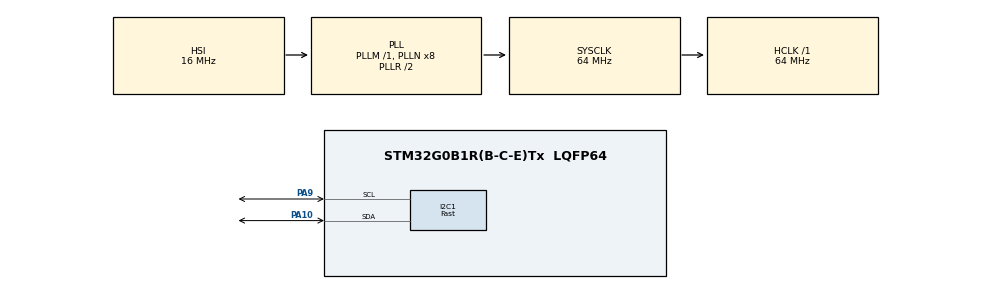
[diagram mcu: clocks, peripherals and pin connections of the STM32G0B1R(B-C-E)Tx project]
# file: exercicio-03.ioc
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I2C1.Analog_Filter=I2C_ANALOGFILTER_DISABLE
I2C1.I2C_Speed_Mode=I2C_Fast
I2C1.Speed=200
I2C1.Timing=0x00603BFF
Mcu.Family=STM32G0
Mcu.Name=STM32G0B1R(B-C-E)Tx
Mcu.Package=LQFP64
PA10.Mode=I2C
PA10.Signal=I2C1_SDA
PA13.Mode=Serial_Wire
PA13.Signal=SYS_SWDIO
PA14-BOOT0.Mode=Serial_Wire
PA14-BOOT0.Signal=SYS_SWCLK
PA9.Mode=I2C
PA9.Signal=I2C1_SCL
ProjectManager.HeapSize=0x200
ProjectManager.StackSize=0x400
ProjectManager.TargetToolchain=STM32CubeIDE
RCC.ADCFreq_Value=64000000
RCC.AHBFreq_Value=64000000
RCC.CortexFreq_Value=64000000
RCC.EXTERNAL_CLOCK_VALUE=48000
RCC.HCLKFreq_Value=64000000
RCC.HSE_VALUE=8000000
RCC.HSI48_VALUE=48000000
RCC.HSI_VALUE=16000000
RCC.LSE_VALUE=32768
RCC.SYSCLKFreq_VALUE=64000000
RCC.SYSCLKSource=RCC_SYSCLKSOURCE_PLLCLK
RCC.USBFreq_Value=48000000
RCC.VCOOutputFreq_Value=128000000
VP_SYS_VS_DBSignals.Mode=DisableDeadBatterySignals
board=custom

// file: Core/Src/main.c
/* USER CODE BEGIN Header */
/**
  ******************************************************************************
  * @file           : main.c
  * @brief          : Main program body
  ******************************************************************************
  * @attention
  *
  * Copyright (c) 2022 STMicroelectronics.
  * All rights reserved.
  *
  * This software is licensed under terms that can be found in the LICENSE file
  * in the root directory of this software component.
  * If no LICENSE file comes with this software, it is provided AS-IS.
  *
  ******************************************************************************
  */
/* USER CODE END Header */
#include "main.h"

/* USER CODE BEGIN Includes */
#include <stdio.h>
#include <stdarg.h>
#include <string.h>
#include "eeprom.h"
/* USER CODE END Includes */

I2C_HandleTypeDef hi2c1;
char memory_dump[1024] = {0}; //8kbit

void SystemClock_Config(void);
static void MX_GPIO_Init(void);
static void MX_I2C1_Init(void);
/* USER CODE BEGIN PFP */
eeprom_t Eeprom;
/* USER CODE END PFP */

/* USER CODE BEGIN 0 */
void vprint(const char *fmt, va_list argp) {
	char string[200];
	if (0 < vsprintf(string, fmt, argp)) // build string
			{
		//HAL_i_Transmit(&huart2, (uint8_t*) string, strlen(string), 0xffffff); // send message via UART
	}
}

void my_printf(const char *fmt, ...) // custom printf() function
{
	va_list argp;
	va_start(argp, fmt);
	vprint(fmt, argp);
	va_end(argp);
}
/* USER CODE END 0 */

int main(void)
{
  /* USER CODE BEGIN 1 */
	uint8_t pDataTx[] = "Pado Labs\n\r";
	uint8_t pDataRx[20];
  /* USER CODE END 1 */

  /* MCU Configuration--------------------------------------------------------*/

  /* Reset of all peripherals, Initializes the Flash interface and the Systick. */
  HAL_Init();

  /* Configure the system clock */
  SystemClock_Config();

  /* Initialize all configured peripherals */
  MX_GPIO_Init();
  MX_I2C1_Init();
  /* USER CODE BEGIN 2 */

  eeprom_init(&Eeprom, &hi2c1, 0xA0, 512);

//  eeprom_write(&Eeprom, 0x10, pDataTx, sizeof(pDataTx));

  eeprom_read(&Eeprom, 0x10, pDataRx, sizeof(pDataTx));
  	//HAL_UART_Transmit(&huart2, (uint8_t*) &memory_dump, sizeof(memory_dump),0xffffff);

  /* USER CODE END 2 */

  /* Infinite loop */
  while (1)
  {

  }
}

void SystemClock_Config(void)
{
  RCC_OscInitTypeDef RCC_OscInitStruct = {0};
  RCC_ClkInitTypeDef RCC_ClkInitStruct = {0};

  /** Configure the main internal regulator output voltage
  */
  HAL_PWREx_ControlVoltageScaling(PWR_REGULATOR_VOLTAGE_SCALE1);
  /** Initializes the RCC Oscillators according to the specified parameters
  * in the RCC_OscInitTypeDef structure.
  */
  RCC_OscInitStruct.OscillatorType = RCC_OSCILLATORTYPE_HSI;
  RCC_OscInitStruct.HSIState = RCC_HSI_ON;
  RCC_OscInitStruct.HSIDiv = RCC_HSI_DIV1;
  RCC_OscInitStruct.HSICalibrationValue = RCC_HSICALIBRATION_DEFAULT;
  RCC_OscInitStruct.PLL.PLLState = RCC_PLL_ON;
  RCC_OscInitStruct.PLL.PLLSource = RCC_PLLSOURCE_HSI;
  RCC_OscInitStruct.PLL.PLLM = RCC_PLLM_DIV1;
  RCC_OscInitStruct.PLL.PLLN = 8;
  RCC_OscInitStruct.PLL.PLLP = RCC_PLLP_DIV2;
  RCC_OscInitStruct.PLL.PLLQ = RCC_PLLQ_DIV2;
  RCC_OscInitStruct.PLL.PLLR = RCC_PLLR_DIV2;
  if (HAL_RCC_OscConfig(&RCC_OscInitStruct) != HAL_OK)
  {
    Error_Handler();
  }
  /** Initializes the CPU, AHB and APB buses clocks
  */
  RCC_ClkInitStruct.ClockType = RCC_CLOCKTYPE_HCLK|RCC_CLOCKTYPE_SYSCLK
                              |RCC_CLOCKTYPE_PCLK1;
  RCC_ClkInitStruct.SYSCLKSource = RCC_SYSCLKSOURCE_PLLCLK;
  RCC_ClkInitStruct.AHBCLKDivider = RCC_SYSCLK_DIV1;
  RCC_ClkInitStruct.APB1CLKDivider = RCC_HCLK_DIV1;

  if (HAL_RCC_ClockConfig(&RCC_ClkInitStruct, FLASH_LATENCY_2) != HAL_OK)
  {
    Error_Handler();
  }
}

static void MX_I2C1_Init(void)
{

  hi2c1.Instance = I2C1;
  hi2c1.Init.Timing = 0x00603BFF;
  hi2c1.Init.OwnAddress1 = 0;
  hi2c1.Init.AddressingMode = I2C_ADDRESSINGMODE_7BIT;
  hi2c1.Init.DualAddressMode = I2C_DUALADDRESS_DISABLE;
  hi2c1.Init.OwnAddress2 = 0;
  hi2c1.Init.OwnAddress2Masks = I2C_OA2_NOMASK;
  hi2c1.Init.GeneralCallMode = I2C_GENERALCALL_DISABLE;
  hi2c1.Init.NoStretchMode = I2C_NOSTRETCH_DISABLE;
  if (HAL_I2C_Init(&hi2c1) != HAL_OK)
  {
    Error_Handler();
  }
  /** Configure Analogue filter
  */
  if (HAL_I2CEx_ConfigAnalogFilter(&hi2c1, I2C_ANALOGFILTER_DISABLE) != HAL_OK)
  {
    Error_Handler();
  }
  /** Configure Digital filter
  */
  if (HAL_I2CEx_ConfigDigitalFilter(&hi2c1, 0) != HAL_OK)
  {
    Error_Handler();
  }

}

static void MX_GPIO_Init(void)
{

  /* GPIO Ports Clock Enable */
  __HAL_RCC_GPIOA_CLK_ENABLE();

}

void Error_Handler(void)
{
  __disable_irq();
  while (1)
  {
  }
}
